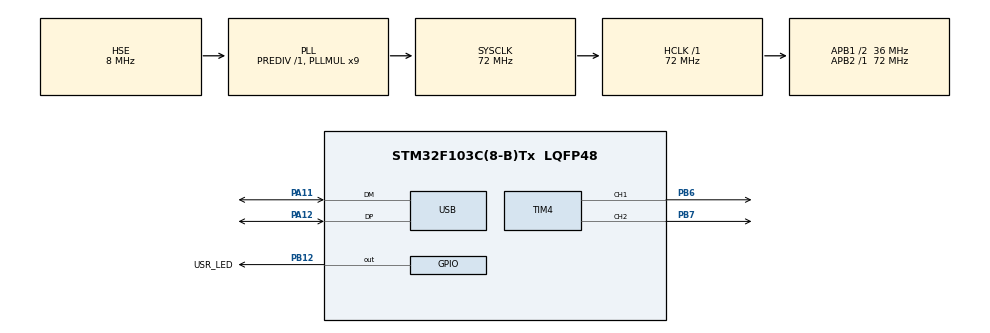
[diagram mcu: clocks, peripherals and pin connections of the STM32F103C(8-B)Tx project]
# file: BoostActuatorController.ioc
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Mcu.Family=STM32F1
Mcu.Name=STM32F103C(8-B)Tx
Mcu.Package=LQFP48
NVIC.PriorityGroup=NVIC_PRIORITYGROUP_4
NVIC.USB_LP_CAN1_RX0_IRQn=true\:0\:0\:false\:false\:true\:false\:true
PA11.Mode=Device
PA11.Signal=USB_DM
PA12.Mode=Device
PA12.Signal=USB_DP
PA13.Mode=Serial_Wire
PA13.Signal=SYS_JTMS-SWDIO
PA14.Mode=Serial_Wire
PA14.Signal=SYS_JTCK-SWCLK
PB12.GPIO_Label=USR_LED
PB12.GPIO_PuPd=GPIO_NOPULL
PB12.Signal=GPIO_Output
PB6.Signal=S_TIM4_CH1
PB7.Signal=S_TIM4_CH2
PD0-OSC_IN.Mode=HSE-External-Oscillator
PD0-OSC_IN.Signal=RCC_OSC_IN
PD1-OSC_OUT.Mode=HSE-External-Oscillator
PD1-OSC_OUT.Signal=RCC_OSC_OUT
ProjectManager.HeapSize=0x200
ProjectManager.StackSize=0x400
ProjectManager.TargetToolchain=Makefile
RCC.AHBFreq_Value=72000000
RCC.APB1CLKDivider=RCC_HCLK_DIV2
RCC.APB1Freq_Value=36000000
RCC.APB1TimFreq_Value=72000000
RCC.APB2Freq_Value=72000000
RCC.APB2TimFreq_Value=72000000
RCC.HCLKFreq_Value=72000000
RCC.PLLMUL=RCC_PLL_MUL9
RCC.SYSCLKFreq_VALUE=72000000
RCC.SYSCLKSource=RCC_SYSCLKSOURCE_PLLCLK
RCC.USBFreq_Value=48000000
RCC.USBPrescaler=RCC_USBCLKSOURCE_PLL_DIV1_5
SH.S_TIM4_CH1.0=TIM4_CH1,PWM Generation1 CH1
SH.S_TIM4_CH2.0=TIM4_CH2,PWM Generation2 CH2
TIM4.Channel-PWM\ Generation1\ CH1=TIM_CHANNEL_1
TIM4.Channel-PWM\ Generation2\ CH2=TIM_CHANNEL_2
TIM4.OCMode_PWM-PWM\ Generation2\ CH2=TIM_OCMODE_PWM1
TIM4.OCPolarity_2=TIM_OCPOLARITY_HIGH
TIM4.Pulse-PWM\ Generation1\ CH1=0
TIM4.Pulse-PWM\ Generation2\ CH2=0
USB_DEVICE.CLASS_NAME_FS=CDC
USB_DEVICE.MANUFACTURER_STRING=Alfoldi Mate
USB_DEVICE.PRODUCT_STRING_CDC_FS=Boost Actuator Controller
USB_DEVICE.VirtualMode=Cdc
USB_DEVICE.VirtualModeFS=Cdc_FS
VP_TIM4_VS_ClockSourceINT.Mode=Internal
VP_USB_DEVICE_VS_USB_DEVICE_CDC_FS.Mode=CDC_FS
board=custom

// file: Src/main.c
/* USER CODE BEGIN Header */
/**
  ******************************************************************************
  * @file           : main.c
  * @brief          : Main program body
  ******************************************************************************
  * @attention
  *
  * <h2><center>&copy; Copyright (c) 2021 STMicroelectronics.
  * All rights reserved.</center></h2>
  *
  * This software component is licensed by ST under Ultimate Liberty license
  * SLA0044, the "License"; You may not use this file except in compliance with
  * the License. You may obtain a copy of the License at:
  *                             www.st.com/SLA0044
  *
  ******************************************************************************
  */
/* USER CODE END Header */
#include "main.h"
#include "tim.h"
#include "usb_device.h"
#include "gpio.h"

/* USER CODE BEGIN Includes */

#include "communication.h"
#include "comm.h"

#include "eeprom.h"

/* USER CODE END Includes */

void SystemClock_Config(void);

int main(void)
{
  /* USER CODE BEGIN 1 */

  COMM_Init(&COMM_DEF_Reg);

  /* USER CODE END 1 */

  /* MCU Configuration--------------------------------------------------------*/

  /* Reset of all peripherals, Initializes the Flash interface and the Systick. */
  HAL_Init();

  /* Configure the system clock */
  SystemClock_Config();

  /* USER CODE BEGIN SysInit */

  /* Unlock the Flash Program Erase controller and eeprop emulator*/
  HAL_FLASH_Unlock();
  EE_Init();

  /* USER CODE END SysInit */

  /* Initialize all configured peripherals */
  MX_GPIO_Init();
  MX_USB_DEVICE_Init();
  MX_TIM4_Init();
  /* USER CODE BEGIN 2 */

  COMM_Data_Init();

  /* USER CODE END 2 */

  /* Infinite loop */
  while (1)
  {

  }
}

void SystemClock_Config(void)
{
  RCC_OscInitTypeDef RCC_OscInitStruct = {0};
  RCC_ClkInitTypeDef RCC_ClkInitStruct = {0};
  RCC_PeriphCLKInitTypeDef PeriphClkInit = {0};

  /** Initializes the RCC Oscillators according to the specified parameters
  * in the RCC_OscInitTypeDef structure.
  */
  RCC_OscInitStruct.OscillatorType = RCC_OSCILLATORTYPE_HSE;
  RCC_OscInitStruct.HSEState = RCC_HSE_ON;
  RCC_OscInitStruct.HSEPredivValue = RCC_HSE_PREDIV_DIV1;
  RCC_OscInitStruct.HSIState = RCC_HSI_ON;
  RCC_OscInitStruct.PLL.PLLState = RCC_PLL_ON;
  RCC_OscInitStruct.PLL.PLLSource = RCC_PLLSOURCE_HSE;
  RCC_OscInitStruct.PLL.PLLMUL = RCC_PLL_MUL9;
  if (HAL_RCC_OscConfig(&RCC_OscInitStruct) != HAL_OK)
  {
    Error_Handler();
  }
  /** Initializes the CPU, AHB and APB buses clocks
  */
  RCC_ClkInitStruct.ClockType = RCC_CLOCKTYPE_HCLK|RCC_CLOCKTYPE_SYSCLK
                              |RCC_CLOCKTYPE_PCLK1|RCC_CLOCKTYPE_PCLK2;
  RCC_ClkInitStruct.SYSCLKSource = RCC_SYSCLKSOURCE_PLLCLK;
  RCC_ClkInitStruct.AHBCLKDivider = RCC_SYSCLK_DIV1;
  RCC_ClkInitStruct.APB1CLKDivider = RCC_HCLK_DIV2;
  RCC_ClkInitStruct.APB2CLKDivider = RCC_HCLK_DIV1;

  if (HAL_RCC_ClockConfig(&RCC_ClkInitStruct, FLASH_LATENCY_2) != HAL_OK)
  {
    Error_Handler();
  }
  PeriphClkInit.PeriphClockSelection = RCC_PERIPHCLK_USB;
  PeriphClkInit.UsbClockSelection = RCC_USBCLKSOURCE_PLL_DIV1_5;
  if (HAL_RCCEx_PeriphCLKConfig(&PeriphClkInit) != HAL_OK)
  {
    Error_Handler();
  }
}

void Error_Handler(void)
{
  __disable_irq();
  while (1)
  {
  }
}

/************************ (C) COPYRIGHT STMicroelectronics *****END OF FILE****/
